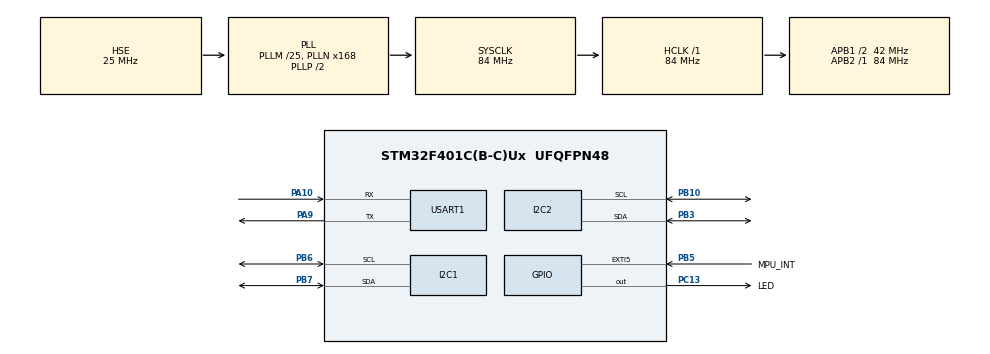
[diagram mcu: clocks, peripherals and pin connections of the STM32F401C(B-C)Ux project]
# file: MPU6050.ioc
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I2C1.I2C_Mode=I2C_Fast
I2C2.I2C_Mode=I2C_Fast
Mcu.Family=STM32F4
Mcu.Name=STM32F401C(B-C)Ux
Mcu.Package=UFQFPN48
NVIC.EXTI9_5_IRQn=true\:0\:0\:false\:false\:true\:true\:true
NVIC.PriorityGroup=NVIC_PRIORITYGROUP_4
PA10.Mode=Asynchronous
PA10.Signal=USART1_RX
PA13.Mode=Serial_Wire
PA13.Signal=SYS_JTMS-SWDIO
PA14.Mode=Serial_Wire
PA14.Signal=SYS_JTCK-SWCLK
PA9.Mode=Asynchronous
PA9.Signal=USART1_TX
PB10.Mode=I2C
PB10.Signal=I2C2_SCL
PB3.Mode=I2C
PB3.Signal=I2C2_SDA
PB5.GPIO_Label=MPU_INT
PB5.GPIO_ModeDefaultEXTI=GPIO_MODE_IT_RISING
PB5.Signal=GPXTI5
PB6.Mode=I2C
PB6.Signal=I2C1_SCL
PB7.Mode=I2C
PB7.Signal=I2C1_SDA
PC13-ANTI_TAMP.GPIO_Label=LED
PC13-ANTI_TAMP.Signal=GPIO_Output
PH0\ -\ OSC_IN.Mode=HSE-External-Oscillator
PH0\ -\ OSC_IN.Signal=RCC_OSC_IN
PH1\ -\ OSC_OUT.Mode=HSE-External-Oscillator
PH1\ -\ OSC_OUT.Signal=RCC_OSC_OUT
ProjectManager.HeapSize=0x200
ProjectManager.StackSize=0x400
ProjectManager.TargetToolchain=Makefile
RCC.48MHZClocksFreq_Value=42000000
RCC.AHBFreq_Value=84000000
RCC.APB1CLKDivider=RCC_HCLK_DIV2
RCC.APB1Freq_Value=42000000
RCC.APB1TimFreq_Value=84000000
RCC.APB2Freq_Value=84000000
RCC.APB2TimFreq_Value=84000000
RCC.CortexFreq_Value=84000000
RCC.HCLKFreq_Value=84000000
RCC.HSE_VALUE=25000000
RCC.HSI_VALUE=16000000
RCC.LSE_VALUE=32768
RCC.PLLM=25
RCC.PLLN=168
RCC.PLLSourceVirtual=RCC_PLLSOURCE_HSE
RCC.SYSCLKFreq_VALUE=84000000
RCC.SYSCLKSource=RCC_SYSCLKSOURCE_PLLCLK
RCC.VCOOutputFreq_Value=168000000
USART1.VirtualMode=VM_ASYNC
board=custom

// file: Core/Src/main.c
/* USER CODE BEGIN Header */
/**
  ******************************************************************************
  * @file           : main.c
  * @brief          : Main program body
  ******************************************************************************
  * @attention
  *
  * <h2><center>&copy; Copyright (c) 2022 STMicroelectronics.
  * All rights reserved.</center></h2>
  *
  * This software component is licensed by ST under BSD 3-Clause license,
  * the "License"; You may not use this file except in compliance with the
  * License. You may obtain a copy of the License at:
  *                        opensource.org/licenses/BSD-3-Clause
  *
  ******************************************************************************
  */
/* USER CODE END Header */
#include "main.h"
#include "i2c.h"
#include "usart.h"
#include "gpio.h"

/* USER CODE BEGIN Includes */
#include "S_SYSTICK.h"
#include "S_MPU6050_MPL.h"
#include "S_UART.h"
/* USER CODE END Includes */

void SystemClock_Config(void);
/* USER CODE BEGIN PFP */
void Show_me_data_f(void)
{
  float pitch,roll,yaw;
  MPUGetData(&pitch,&roll,&yaw);

  UART_printf(&huart1,":%.2f,%.2f,%.2f\n",pitch,roll,yaw);
}
/* USER CODE END PFP */

int main(void)
{

  /* MCU Configuration--------------------------------------------------------*/

  /* Reset of all peripherals, Initializes the Flash interface and the Systick. */
  HAL_Init();

  /* Configure the system clock */
  SystemClock_Config();

  /* Initialize all configured peripherals */
  MX_GPIO_Init();
  MX_I2C1_Init();
  MX_USART1_UART_Init();
  MX_I2C2_Init();
  /* USER CODE BEGIN 2 */
  MPU6050_Init();
  Period_t show_me_data = {.fun = &Show_me_data_f,.n=-1,.period=10,.TargetTick=0};
  /* USER CODE END 2 */

  /* Infinite loop */
  while (1)
  {

    /* USER CODE BEGIN 3 */
    do_sth_period(&show_me_data);
  }
  /* USER CODE END 3 */
}

void SystemClock_Config(void)
{
  RCC_OscInitTypeDef RCC_OscInitStruct = {0};
  RCC_ClkInitTypeDef RCC_ClkInitStruct = {0};

  /** Configure the main internal regulator output voltage
  */
  __HAL_RCC_PWR_CLK_ENABLE();
  __HAL_PWR_VOLTAGESCALING_CONFIG(PWR_REGULATOR_VOLTAGE_SCALE2);
  /** Initializes the RCC Oscillators according to the specified parameters
  * in the RCC_OscInitTypeDef structure.
  */
  RCC_OscInitStruct.OscillatorType = RCC_OSCILLATORTYPE_HSE;
  RCC_OscInitStruct.HSEState = RCC_HSE_ON;
  RCC_OscInitStruct.PLL.PLLState = RCC_PLL_ON;
  RCC_OscInitStruct.PLL.PLLSource = RCC_PLLSOURCE_HSE;
  RCC_OscInitStruct.PLL.PLLM = 25;
  RCC_OscInitStruct.PLL.PLLN = 168;
  RCC_OscInitStruct.PLL.PLLP = RCC_PLLP_DIV2;
  RCC_OscInitStruct.PLL.PLLQ = 4;
  if (HAL_RCC_OscConfig(&RCC_OscInitStruct) != HAL_OK)
  {
    Error_Handler();
  }
  /** Initializes the CPU, AHB and APB buses clocks
  */
  RCC_ClkInitStruct.ClockType = RCC_CLOCKTYPE_HCLK|RCC_CLOCKTYPE_SYSCLK
                              |RCC_CLOCKTYPE_PCLK1|RCC_CLOCKTYPE_PCLK2;
  RCC_ClkInitStruct.SYSCLKSource = RCC_SYSCLKSOURCE_PLLCLK;
  RCC_ClkInitStruct.AHBCLKDivider = RCC_SYSCLK_DIV1;
  RCC_ClkInitStruct.APB1CLKDivider = RCC_HCLK_DIV2;
  RCC_ClkInitStruct.APB2CLKDivider = RCC_HCLK_DIV1;

  if (HAL_RCC_ClockConfig(&RCC_ClkInitStruct, FLASH_LATENCY_2) != HAL_OK)
  {
    Error_Handler();
  }
}

void Error_Handler(void)
{
  __disable_irq();
  while (1)
  {
  }
}

/************************ (C) COPYRIGHT STMicroelectronics *****END OF FILE****/
